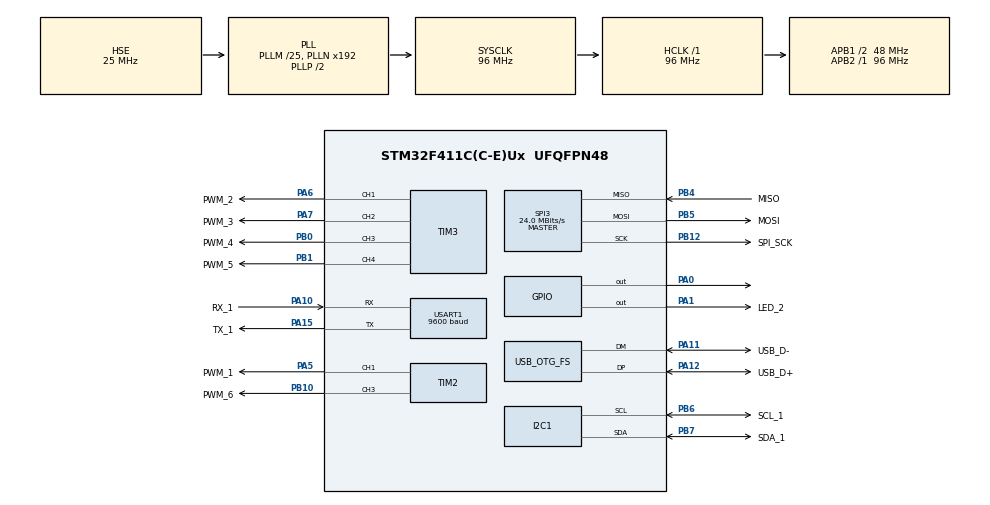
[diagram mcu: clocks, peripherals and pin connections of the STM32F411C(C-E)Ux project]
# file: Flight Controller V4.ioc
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ADC1.Channel-0\#ChannelRegularConversion=ADC_CHANNEL_TEMPSENSOR
ADC1.NbrOfConversionFlag=1
ADC1.Rank-0\#ChannelRegularConversion=1
ADC1.SamplingTime-0\#ChannelRegularConversion=ADC_SAMPLETIME_3CYCLES
ADC1.master=1
Mcu.Family=STM32F4
Mcu.Name=STM32F411C(C-E)Ux
Mcu.Package=UFQFPN48
NVIC.OTG_FS_IRQn=true\:0\:0\:false\:false\:true\:false\:true\:true
NVIC.PriorityGroup=NVIC_PRIORITYGROUP_4
PA0-WKUP.Signal=GPIO_Output
PA1.GPIO_Label=LED_2
PA1.Signal=GPIO_Output
PA10.GPIO_Label=RX_1
PA10.Mode=Asynchronous
PA10.Signal=USART1_RX
PA11.GPIO_Label=USB_D-
PA11.Mode=Device_Only
PA11.Signal=USB_OTG_FS_DM
PA12.GPIO_Label=USB_D+
PA12.Mode=Device_Only
PA12.Signal=USB_OTG_FS_DP
PA13.GPIO_Label=SWDIO
PA13.Mode=Serial_Wire
PA13.Signal=SYS_JTMS-SWDIO
PA14.GPIO_Label=SWCLK
PA14.Mode=Serial_Wire
PA14.Signal=SYS_JTCK-SWCLK
PA15.GPIO_Label=TX_1
PA15.Mode=Asynchronous
PA15.Signal=USART1_TX
PA5.GPIO_Label=PWM_1
PA5.Signal=S_TIM2_CH1_ETR
PA6.GPIO_Label=PWM_2
PA6.Signal=S_TIM3_CH1
PA7.GPIO_Label=PWM_3
PA7.Signal=S_TIM3_CH2
PB0.GPIO_Label=PWM_4
PB0.Signal=S_TIM3_CH3
PB1.GPIO_Label=PWM_5
PB1.Signal=S_TIM3_CH4
PB10.GPIO_Label=PWM_6
PB10.Signal=S_TIM2_CH3
PB12.GPIO_Label=SPI_SCK
PB12.Mode=Full_Duplex_Master
PB12.Signal=SPI3_SCK
PB3.GPIO_Label=SWO
PB3.Signal=SYS_JTDO-SWO
PB4.GPIO_Label=MISO
PB4.Mode=Full_Duplex_Master
PB4.Signal=SPI3_MISO
PB5.GPIO_Label=MOSI
PB5.Mode=Full_Duplex_Master
PB5.Signal=SPI3_MOSI
PB6.GPIO_Label=SCL_1
PB6.Mode=I2C
PB6.Signal=I2C1_SCL
PB7.GPIO_Label=SDA_1
PB7.Mode=I2C
PB7.Signal=I2C1_SDA
PH0\ -\ OSC_IN.GPIO_Label=CLK_IN
PH0\ -\ OSC_IN.Mode=HSE-External-Clock-Source
PH0\ -\ OSC_IN.Signal=RCC_OSC_IN
PH1\ -\ OSC_OUT.GPIO_Label=CLK_OUT
PH1\ -\ OSC_OUT.Mode=HSE-External-Clock-Source
PH1\ -\ OSC_OUT.Signal=RCC_OSC_OUT
ProjectManager.HeapSize=0x200
ProjectManager.StackSize=0x400
ProjectManager.TargetToolchain=STM32CubeIDE
RCC.48MHZClocksFreq_Value=48000000
RCC.AHBFreq_Value=96000000
RCC.APB1CLKDivider=RCC_HCLK_DIV2
RCC.APB1Freq_Value=48000000
RCC.APB1TimFreq_Value=96000000
RCC.APB2Freq_Value=96000000
RCC.APB2TimFreq_Value=96000000
RCC.CortexFreq_Value=96000000
RCC.HCLKFreq_Value=96000000
RCC.HSE_VALUE=25000000
RCC.HSI_VALUE=16000000
RCC.LSE_VALUE=32768
RCC.PLLM=25
RCC.SYSCLKFreq_VALUE=96000000
RCC.SYSCLKSource=RCC_SYSCLKSOURCE_PLLCLK
RCC.VCOOutputFreq_Value=192000000
SH.S_TIM2_CH1_ETR.0=TIM2_CH1,PWM Generation1 CH1
SH.S_TIM2_CH3.0=TIM2_CH3,PWM Generation3 CH3
SH.S_TIM3_CH1.0=TIM3_CH1,PWM Generation1 CH1
SH.S_TIM3_CH2.0=TIM3_CH2,PWM Generation2 CH2
SH.S_TIM3_CH3.0=TIM3_CH3,PWM Generation3 CH3
SH.S_TIM3_CH4.0=TIM3_CH4,PWM Generation4 CH4
SPI3.CalculateBaudRate=24.0 MBits/s
SPI3.Direction=SPI_DIRECTION_2LINES
SPI3.Mode=SPI_MODE_MASTER
SPI3.VirtualType=VM_MASTER
TIM2.Channel-PWM\ Generation1\ CH1=TIM_CHANNEL_1
TIM2.Channel-PWM\ Generation3\ CH3=TIM_CHANNEL_3
TIM3.Channel-PWM\ Generation1\ CH1=TIM_CHANNEL_1
TIM3.Channel-PWM\ Generation2\ CH2=TIM_CHANNEL_2
TIM3.Channel-PWM\ Generation3\ CH3=TIM_CHANNEL_3
TIM3.Channel-PWM\ Generation4\ CH4=TIM_CHANNEL_4
USART1.BaudRate=9600
USART1.VirtualMode=VM_ASYNC
USB_DEVICE.CLASS_NAME_FS=CDC
USB_DEVICE.VirtualMode=Cdc
USB_DEVICE.VirtualModeFS=Cdc_FS
USB_OTG_FS.VirtualMode=Device_Only
VP_ADC1_TempSens_Input.Mode=IN-TempSens
VP_ADC1_Vref_Input.Mode=IN-Vrefint
VP_IWDG_VS_IWDG.Mode=IWDG_Activate
VP_TIM2_VS_ClockSourceINT.Mode=Internal
VP_TIM3_VS_ClockSourceINT.Mode=Internal
VP_USB_DEVICE_VS_USB_DEVICE_CDC_FS.Mode=CDC_FS
board=custom

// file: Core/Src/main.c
/* USER CODE BEGIN Header */
/**
  ******************************************************************************
  * @file    main.c
  * @brief   Hyades FC-V4 (STM32F411CEU @ 96 MHz): CubeMX peripheral init, then
  *          App_Run() (Core/Src/app.c), which never returns. All application
  *          code lives outside this generated file; see app.h for the layering.
  ******************************************************************************
  */
/* USER CODE END Header */
#include "main.h"
#include "usb_device.h"

/* USER CODE BEGIN Includes */
#include "app.h"
/* USER CODE END Includes */

ADC_HandleTypeDef hadc1;

I2C_HandleTypeDef hi2c1;

IWDG_HandleTypeDef hiwdg;

SPI_HandleTypeDef hspi3;

TIM_HandleTypeDef htim2;
TIM_HandleTypeDef htim3;

UART_HandleTypeDef huart1;

void SystemClock_Config(void);
static void MX_GPIO_Init(void);
static void MX_ADC1_Init(void);
static void MX_I2C1_Init(void);
static void MX_TIM2_Init(void);
static void MX_USART1_UART_Init(void);
static void MX_TIM3_Init(void);
static void MX_SPI3_Init(void);
static void MX_IWDG_Init(void);
/* USER CODE BEGIN PFP */
static void MX_IWDG_Init(void) __attribute__((unused));  /* IWDG is driven by wdg.c */

/* USER CODE END PFP */

int main(void)
{

  /* MCU Configuration--------------------------------------------------------*/

  /* Reset of all peripherals, Initializes the Flash interface and the Systick. */
  HAL_Init();

  /* Configure the system clock */
  SystemClock_Config();

  /* Initialize all configured peripherals */
  MX_GPIO_Init();
  MX_ADC1_Init();
  MX_I2C1_Init();
  MX_TIM2_Init();
  MX_USART1_UART_Init();
  MX_TIM3_Init();
  MX_SPI3_Init();
  MX_USB_DEVICE_Init();
  //MX_IWDG_Init();
  /* USER CODE BEGIN 2 */
  App_Run(&hi2c1, &huart1);      /* never returns */
  /* USER CODE END 2 */

  /* Infinite loop */
  while (1)
  {

  }
}

void SystemClock_Config(void)
{
  RCC_OscInitTypeDef RCC_OscInitStruct = {0};
  RCC_ClkInitTypeDef RCC_ClkInitStruct = {0};

  /** Configure the main internal regulator output voltage
  */
  __HAL_RCC_PWR_CLK_ENABLE();
  __HAL_PWR_VOLTAGESCALING_CONFIG(PWR_REGULATOR_VOLTAGE_SCALE1);

  /** Initializes the RCC Oscillators according to the specified parameters
  * in the RCC_OscInitTypeDef structure.
  */
  RCC_OscInitStruct.OscillatorType = RCC_OSCILLATORTYPE_LSI|RCC_OSCILLATORTYPE_HSE;
  RCC_OscInitStruct.HSEState = RCC_HSE_BYPASS;
  RCC_OscInitStruct.LSIState = RCC_LSI_ON;
  RCC_OscInitStruct.PLL.PLLState = RCC_PLL_ON;
  RCC_OscInitStruct.PLL.PLLSource = RCC_PLLSOURCE_HSE;
  RCC_OscInitStruct.PLL.PLLM = 25;
  RCC_OscInitStruct.PLL.PLLN = 192;
  RCC_OscInitStruct.PLL.PLLP = RCC_PLLP_DIV2;
  RCC_OscInitStruct.PLL.PLLQ = 4;
  if (HAL_RCC_OscConfig(&RCC_OscInitStruct) != HAL_OK)
  {
    Error_Handler();
  }

  /** Initializes the CPU, AHB and APB buses clocks
  */
  RCC_ClkInitStruct.ClockType = RCC_CLOCKTYPE_HCLK|RCC_CLOCKTYPE_SYSCLK
                              |RCC_CLOCKTYPE_PCLK1|RCC_CLOCKTYPE_PCLK2;
  RCC_ClkInitStruct.SYSCLKSource = RCC_SYSCLKSOURCE_PLLCLK;
  RCC_ClkInitStruct.AHBCLKDivider = RCC_SYSCLK_DIV1;
  RCC_ClkInitStruct.APB1CLKDivider = RCC_HCLK_DIV2;
  RCC_ClkInitStruct.APB2CLKDivider = RCC_HCLK_DIV1;

  if (HAL_RCC_ClockConfig(&RCC_ClkInitStruct, FLASH_LATENCY_3) != HAL_OK)
  {
    Error_Handler();
  }
}

static void MX_ADC1_Init(void)
{

  ADC_ChannelConfTypeDef sConfig = {0};

  /** Configure the global features of the ADC (Clock, Resolution, Data Alignment and number of conversion)
  */
  hadc1.Instance = ADC1;
  hadc1.Init.ClockPrescaler = ADC_CLOCK_SYNC_PCLK_DIV4;
  hadc1.Init.Resolution = ADC_RESOLUTION_12B;
  hadc1.Init.ScanConvMode = DISABLE;
  hadc1.Init.ContinuousConvMode = DISABLE;
  hadc1.Init.DiscontinuousConvMode = DISABLE;
  hadc1.Init.ExternalTrigConvEdge = ADC_EXTERNALTRIGCONVEDGE_NONE;
  hadc1.Init.ExternalTrigConv = ADC_SOFTWARE_START;
  hadc1.Init.DataAlign = ADC_DATAALIGN_RIGHT;
  hadc1.Init.NbrOfConversion = 1;
  hadc1.Init.DMAContinuousRequests = DISABLE;
  hadc1.Init.EOCSelection = ADC_EOC_SINGLE_CONV;
  if (HAL_ADC_Init(&hadc1) != HAL_OK)
  {
    Error_Handler();
  }

  /** Configure for the selected ADC regular channel its corresponding rank in the sequencer and its sample time.
  */
  sConfig.Channel = ADC_CHANNEL_TEMPSENSOR;
  sConfig.Rank = 1;
  sConfig.SamplingTime = ADC_SAMPLETIME_3CYCLES;
  if (HAL_ADC_ConfigChannel(&hadc1, &sConfig) != HAL_OK)
  {
    Error_Handler();
  }

}

static void MX_I2C1_Init(void)
{

  hi2c1.Instance = I2C1;
  hi2c1.Init.ClockSpeed = 100000;
  hi2c1.Init.DutyCycle = I2C_DUTYCYCLE_2;
  hi2c1.Init.OwnAddress1 = 0;
  hi2c1.Init.AddressingMode = I2C_ADDRESSINGMODE_7BIT;
  hi2c1.Init.DualAddressMode = I2C_DUALADDRESS_DISABLE;
  hi2c1.Init.OwnAddress2 = 0;
  hi2c1.Init.GeneralCallMode = I2C_GENERALCALL_DISABLE;
  hi2c1.Init.NoStretchMode = I2C_NOSTRETCH_DISABLE;
  if (HAL_I2C_Init(&hi2c1) != HAL_OK)
  {
    Error_Handler();
  }

}

static void MX_IWDG_Init(void)
{

  /* USER CODE BEGIN IWDG_Init 0 */
  __HAL_DBGMCU_FREEZE_IWDG();   /* watchdog paused while the core is halted by the debugger */

  /* USER CODE END IWDG_Init 0 */

  hiwdg.Instance = IWDG;
  hiwdg.Init.Prescaler = IWDG_PRESCALER_4;
  hiwdg.Init.Reload = 800;      /* LSI 32 kHz /4 -> ~100 ms (68-188 ms over LSI spread) = 10 frames */
  if (HAL_IWDG_Init(&hiwdg) != HAL_OK)
  {
    Error_Handler();
  }

}

static void MX_SPI3_Init(void)
{

  /* SPI3 parameter configuration*/
  hspi3.Instance = SPI3;
  hspi3.Init.Mode = SPI_MODE_MASTER;
  hspi3.Init.Direction = SPI_DIRECTION_2LINES;
  hspi3.Init.DataSize = SPI_DATASIZE_8BIT;
  hspi3.Init.CLKPolarity = SPI_POLARITY_LOW;
  hspi3.Init.CLKPhase = SPI_PHASE_1EDGE;
  hspi3.Init.NSS = SPI_NSS_SOFT;
  hspi3.Init.BaudRatePrescaler = SPI_BAUDRATEPRESCALER_2;
  hspi3.Init.FirstBit = SPI_FIRSTBIT_MSB;
  hspi3.Init.TIMode = SPI_TIMODE_DISABLE;
  hspi3.Init.CRCCalculation = SPI_CRCCALCULATION_DISABLE;
  hspi3.Init.CRCPolynomial = 10;
  if (HAL_SPI_Init(&hspi3) != HAL_OK)
  {
    Error_Handler();
  }

}

static void MX_TIM2_Init(void)
{

  TIM_ClockConfigTypeDef sClockSourceConfig = {0};
  TIM_MasterConfigTypeDef sMasterConfig = {0};
  TIM_OC_InitTypeDef sConfigOC = {0};

  htim2.Instance = TIM2;
  htim2.Init.Prescaler = 0;
  htim2.Init.CounterMode = TIM_COUNTERMODE_UP;
  htim2.Init.Period = 4294967295;
  htim2.Init.ClockDivision = TIM_CLOCKDIVISION_DIV1;
  htim2.Init.AutoReloadPreload = TIM_AUTORELOAD_PRELOAD_DISABLE;
  if (HAL_TIM_Base_Init(&htim2) != HAL_OK)
  {
    Error_Handler();
  }
  sClockSourceConfig.ClockSource = TIM_CLOCKSOURCE_INTERNAL;
  if (HAL_TIM_ConfigClockSource(&htim2, &sClockSourceConfig) != HAL_OK)
  {
    Error_Handler();
  }
  if (HAL_TIM_PWM_Init(&htim2) != HAL_OK)
  {
    Error_Handler();
  }
  sMasterConfig.MasterOutputTrigger = TIM_TRGO_RESET;
  sMasterConfig.MasterSlaveMode = TIM_MASTERSLAVEMODE_DISABLE;
  if (HAL_TIMEx_MasterConfigSynchronization(&htim2, &sMasterConfig) != HAL_OK)
  {
    Error_Handler();
  }
  sConfigOC.OCMode = TIM_OCMODE_PWM1;
  sConfigOC.Pulse = 0;
  sConfigOC.OCPolarity = TIM_OCPOLARITY_HIGH;
  sConfigOC.OCFastMode = TIM_OCFAST_DISABLE;
  if (HAL_TIM_PWM_ConfigChannel(&htim2, &sConfigOC, TIM_CHANNEL_1) != HAL_OK)
  {
    Error_Handler();
  }
  if (HAL_TIM_PWM_ConfigChannel(&htim2, &sConfigOC, TIM_CHANNEL_3) != HAL_OK)
  {
    Error_Handler();
  }
  HAL_TIM_MspPostInit(&htim2);

}

static void MX_TIM3_Init(void)
{

  TIM_ClockConfigTypeDef sClockSourceConfig = {0};
  TIM_MasterConfigTypeDef sMasterConfig = {0};
  TIM_OC_InitTypeDef sConfigOC = {0};

  htim3.Instance = TIM3;
  htim3.Init.Prescaler = 0;
  htim3.Init.CounterMode = TIM_COUNTERMODE_UP;
  htim3.Init.Period = 65535;
  htim3.Init.ClockDivision = TIM_CLOCKDIVISION_DIV1;
  htim3.Init.AutoReloadPreload = TIM_AUTORELOAD_PRELOAD_DISABLE;
  if (HAL_TIM_Base_Init(&htim3) != HAL_OK)
  {
    Error_Handler();
  }
  sClockSourceConfig.ClockSource = TIM_CLOCKSOURCE_INTERNAL;
  if (HAL_TIM_ConfigClockSource(&htim3, &sClockSourceConfig) != HAL_OK)
  {
    Error_Handler();
  }
  if (HAL_TIM_PWM_Init(&htim3) != HAL_OK)
  {
    Error_Handler();
  }
  sMasterConfig.MasterOutputTrigger = TIM_TRGO_RESET;
  sMasterConfig.MasterSlaveMode = TIM_MASTERSLAVEMODE_DISABLE;
  if (HAL_TIMEx_MasterConfigSynchronization(&htim3, &sMasterConfig) != HAL_OK)
  {
    Error_Handler();
  }
  sConfigOC.OCMode = TIM_OCMODE_PWM1;
  sConfigOC.Pulse = 0;
  sConfigOC.OCPolarity = TIM_OCPOLARITY_HIGH;
  sConfigOC.OCFastMode = TIM_OCFAST_DISABLE;
  if (HAL_TIM_PWM_ConfigChannel(&htim3, &sConfigOC, TIM_CHANNEL_1) != HAL_OK)
  {
    Error_Handler();
  }
  if (HAL_TIM_PWM_ConfigChannel(&htim3, &sConfigOC, TIM_CHANNEL_2) != HAL_OK)
  {
    Error_Handler();
  }
  if (HAL_TIM_PWM_ConfigChannel(&htim3, &sConfigOC, TIM_CHANNEL_3) != HAL_OK)
  {
    Error_Handler();
  }
  if (HAL_TIM_PWM_ConfigChannel(&htim3, &sConfigOC, TIM_CHANNEL_4) != HAL_OK)
  {
    Error_Handler();
  }
  HAL_TIM_MspPostInit(&htim3);

}

static void MX_USART1_UART_Init(void)
{

  huart1.Instance = USART1;
  huart1.Init.BaudRate = 9600;
  huart1.Init.WordLength = UART_WORDLENGTH_8B;
  huart1.Init.StopBits = UART_STOPBITS_1;
  huart1.Init.Parity = UART_PARITY_NONE;
  huart1.Init.Mode = UART_MODE_TX_RX;
  huart1.Init.HwFlowCtl = UART_HWCONTROL_NONE;
  huart1.Init.OverSampling = UART_OVERSAMPLING_16;
  if (HAL_UART_Init(&huart1) != HAL_OK)
  {
    Error_Handler();
  }

}

static void MX_GPIO_Init(void)
{
  GPIO_InitTypeDef GPIO_InitStruct = {0};

  /* GPIO Ports Clock Enable */
  __HAL_RCC_GPIOH_CLK_ENABLE();
  __HAL_RCC_GPIOA_CLK_ENABLE();
  __HAL_RCC_GPIOB_CLK_ENABLE();

  /*Configure GPIO pin Output Level */
  HAL_GPIO_WritePin(GPIOA, GPIO_PIN_0|LED_2_Pin, GPIO_PIN_RESET);

  /*Configure GPIO pins : PA0 LED_2_Pin */
  GPIO_InitStruct.Pin = GPIO_PIN_0|LED_2_Pin;
  GPIO_InitStruct.Mode = GPIO_MODE_OUTPUT_PP;
  GPIO_InitStruct.Pull = GPIO_NOPULL;
  GPIO_InitStruct.Speed = GPIO_SPEED_FREQ_LOW;
  HAL_GPIO_Init(GPIOA, &GPIO_InitStruct);

}

void Error_Handler(void)
{
  __disable_irq();
  while (1)
  {
  }
}
